VERSION ""

NS_ :

BS_:

BU_: UW_HS2_Bus HSC

BO_ 1972 SigAttack_10ms_10mics: 1 HSC
 SG_ SigAtk_10ms10mics : 0|8@1+ (1,0) [0|255] ""  UW_HS2_Bus

BO_ 1971 SigAttack_10ms_5mics: 1 HSC
 SG_ SigAtk_10ms5mics : 0|8@1+ (1,0) [0|255] ""  UW_HS2_Bus

BO_ 1970 SigAttack_10ms_1mics: 1 HSC
 SG_ SigAtk_10ms1mics : 0|8@1+ (1,0) [0|255] ""  UW_HS2_Bus

BO_ 1973 SigAttack_10ms_0mics: 1 HSC
 SG_ SigAtk_10ms0mics : 0|8@1+ (1,0) [0|255] ""  UW_HS2_Bus

BO_ 1967 SteeringWhl_Signals: 4 HSC
 SG_ StrWhlAngGrd : 16|12@1- (1,0) [-2048|2047] "deg/sec"  UW_HS2_Bus
 SG_ StrWhlAng : 0|16@1- (0.0625,0) [-2048|2047.94] "deg"  UW_HS2_Bus

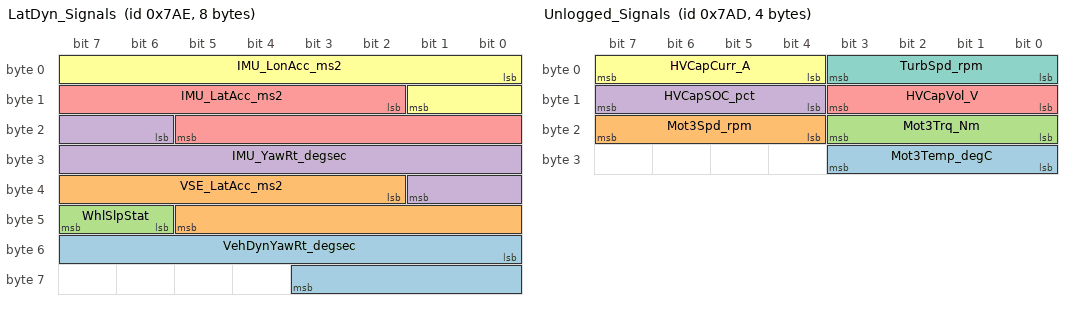
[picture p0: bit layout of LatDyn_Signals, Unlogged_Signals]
BO_ 1966 LatDyn_Signals: 8 HSC
 SG_ VehDynYawRt_degsec : 48|12@1- (0.0625,0) [-128|127.938] "deg/sec"  UW_HS2_Bus
 SG_ VSE_LatAcc_ms2 : 34|12@1- (0.015625,0) [-32|31.9844] "m/s^2"  UW_HS2_Bus
 SG_ WhlSlpStat : 46|2@1+ (1,0) [0|3] ""  UW_HS2_Bus
 SG_ IMU_YawRt_degsec : 22|12@1- (0.0625,0) [-128|127.938] "deg/sec"  UW_HS2_Bus
 SG_ IMU_LatAcc_ms2 : 10|12@1- (0.015625,0) [-32|31.9844] "m/s^2"  UW_HS2_Bus
 SG_ IMU_LonAcc_ms2 : 0|10@1- (0.03,0) [-15.36|15.33] "m/s^2"  UW_HS2_Bus

BO_ 1965 Unlogged_Signals: 4 HSC
 SG_ Mot3Temp_degC : 24|4@1+ (1,0) [0|15] "degC" Vector__XXX
 SG_ Mot3Spd_rpm : 20|4@1+ (1,0) [0|15] "rpm" Vector__XXX
 SG_ Mot3Trq_Nm : 16|4@1+ (1,0) [0|15] "Nm" Vector__XXX
 SG_ HVCapSOC_pct : 12|4@1+ (1,0) [0|15] "%" Vector__XXX
 SG_ HVCapVol_V : 8|4@1+ (1,0) [0|15] "V" Vector__XXX
 SG_ HVCapCurr_A : 4|4@1+ (1,0) [0|15] "A" Vector__XXX
 SG_ TurbSpd_rpm : 0|4@1+ (1,0) [0|15] "rpm" Vector__XXX

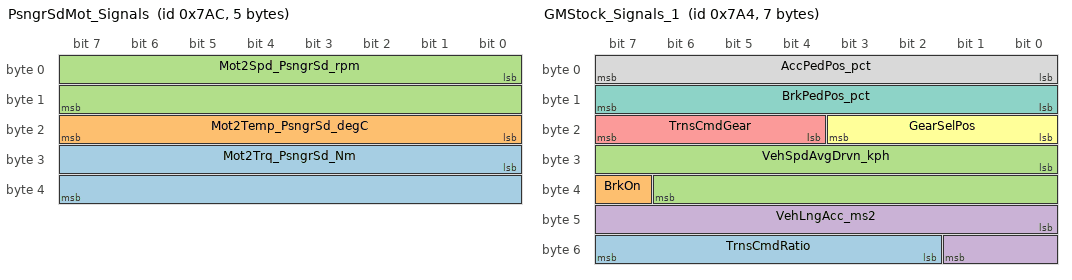
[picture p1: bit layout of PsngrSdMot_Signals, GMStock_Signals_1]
BO_ 1964 PsngrSdMot_Signals: 5 HSC
 SG_ Mot2Trq_PsngrSd_Nm : 24|16@1+ (0.01526,-500) [-500|500.0641] "Nm"  UW_HS2_Bus
 SG_ Mot2Temp_PsngrSd_degC : 16|8@1+ (1,-40) [-40|215] "degC"  UW_HS2_Bus
 SG_ Mot2Spd_PsngrSd_rpm : 0|16@1+ (1,-32767) [-32767|32768] "rpm"  UW_HS2_Bus

BO_ 1956 GMStock_Signals_1: 7 HSC
 SG_ TrnsCmdRatio : 50|6@1+ (0.2,0) [0|12.6] "" Vector__XXX
 SG_ BrkOn : 39|1@1+ (1,0) [0|1] ""  UW_HS2_Bus
 SG_ VehSpdAvgDrvn_kph : 24|15@1+ (0.015625,0) [0|511.984] "km / h"  UW_HS2_Bus
 SG_ VehLngAcc_ms2 : 40|10@1- (0.03,0) [-15.36|15.33] "m/s^2"  UW_HS2_Bus
 SG_ TrnsCmdGear : 20|4@1+ (1,0) [0|15] ""  UW_HS2_Bus
 SG_ GearSelPos : 16|4@1+ (1,0) [0|15] ""  UW_HS2_Bus
 SG_ BrkPedPos_pct : 8|8@1+ (0.392157,0) [0|100] "% full"  UW_HS2_Bus
 SG_ AccPedPos_pct : 0|8@1+ (0.392157,0) [0|100] "%"  UW_HS2_Bus

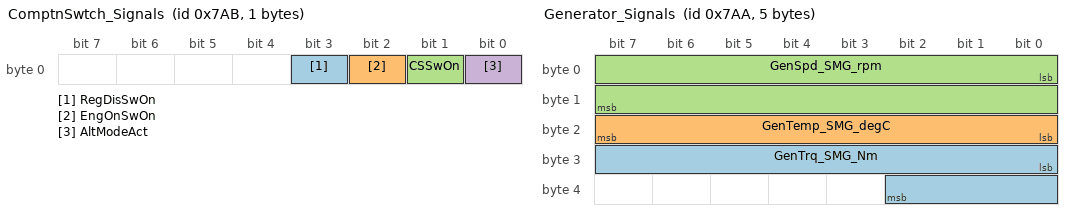
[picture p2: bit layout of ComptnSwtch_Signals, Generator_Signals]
BO_ 1963 ComptnSwtch_Signals: 1 HSC
 SG_ RegDisSwOn : 3|1@1+ (1,0) [0|1] ""  UW_HS2_Bus
 SG_ EngOnSwOn : 2|1@1+ (1,0) [0|1] ""  UW_HS2_Bus
 SG_ CSSwOn : 1|1@1+ (1,0) [0|1] ""  UW_HS2_Bus
 SG_ AltModeAct : 0|1@1+ (1,0) [0|1] ""  UW_HS2_Bus

BO_ 1962 Generator_Signals: 5 HSC
 SG_ GenTrq_SMG_Nm : 24|11@1+ (1,-1023) [-1023|1024] "Nm"  UW_HS2_Bus
 SG_ GenTemp_SMG_degC : 16|8@1+ (1,-40) [-40|215] "degC"  UW_HS2_Bus
 SG_ GenSpd_SMG_rpm : 0|16@1+ (1,-32767) [-32767|32768] "rpm"  UW_HS2_Bus

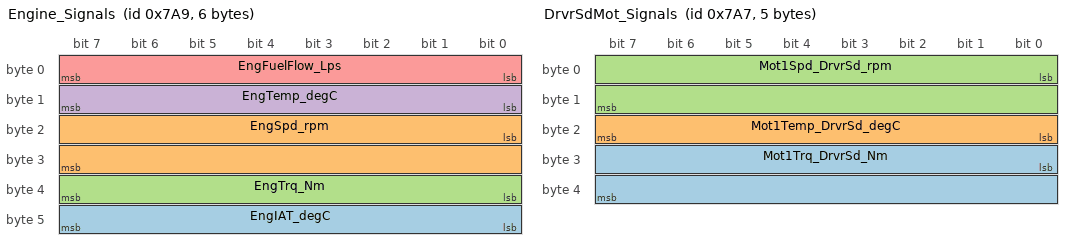
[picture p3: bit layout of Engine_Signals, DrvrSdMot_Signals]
BO_ 1961 Engine_Signals: 6 HSC
 SG_ EngIAT_degC : 40|8@1+ (1,-40) [-40|215] "degC" Vector__XXX
 SG_ EngSpd_rpm : 16|16@1+ (1,-32767) [-32767|32768] "rpm" Vector__XXX
 SG_ EngTrq_Nm : 32|8@1+ (0.3137,0) [0|60] "Nm"  UW_HS2_Bus
 SG_ EngTemp_degC : 8|8@1+ (1,-40) [-40|215] "degC"  UW_HS2_Bus
 SG_ EngFuelFlow_Lps : 0|8@1+ (1,0) [0|0.02] "Litre/s"  UW_HS2_Bus

BO_ 1960 Charger_Signals: 4 HSC
 SG_ ChrgACVolt_V : 16|16@1+ (0.1,0) [0|500] ""  UW_HS2_Bus
 SG_ ChrgACCurr_A : 0|16@1+ (0.01,0) [0|50] ""  UW_HS2_Bus

BO_ 1959 DrvrSdMot_Signals: 5 HSC
 SG_ Mot1Trq_DrvrSd_Nm : 24|16@1+ (0.01526,-500) [-500|500.0641] "Nm"  UW_HS2_Bus
 SG_ Mot1Temp_DrvrSd_degC : 16|8@1+ (1,-40) [-40|215] "degC"  UW_HS2_Bus
 SG_ Mot1Spd_DrvrSd_rpm : 0|16@1+ (1,-32767) [-32767|32768] "rpm"  UW_HS2_Bus

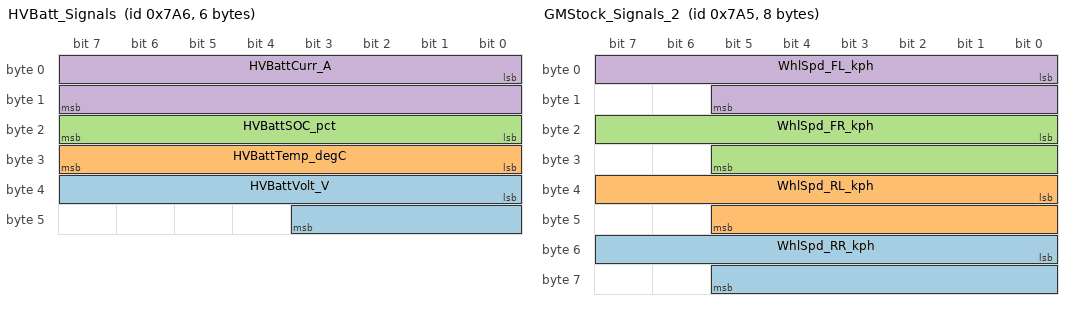
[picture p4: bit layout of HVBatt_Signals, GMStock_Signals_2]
BO_ 1958 HVBatt_Signals: 6 HSC
 SG_ HVBattVolt_V : 32|12@1+ (0.25,0) [0|1000] "Volts"  UW_HS2_Bus
 SG_ HVBattTemp_degC : 24|8@1+ (0.5,-40) [-40|85] "degC"  UW_HS2_Bus
 SG_ HVBattSOC_pct : 16|8@1+ (0.5,0) [0|100] "%"  UW_HS2_Bus
 SG_ HVBattCurr_A : 0|16@1+ (0.025,-1000) [-1000|500] "Amps"  UW_HS2_Bus

BO_ 1957 GMStock_Signals_2: 8 HSC
 SG_ WhlSpd_RR_kph : 48|14@1+ (0.03125,0) [0|511.969] "km / h"  UW_HS2_Bus
 SG_ WhlSpd_RL_kph : 32|14@1+ (0.03125,0) [0|511.969] "km / h"  UW_HS2_Bus
 SG_ WhlSpd_FR_kph : 16|14@1+ (0.03125,0) [0|511.969] "km / h"  UW_HS2_Bus
 SG_ WhlSpd_FL_kph : 0|14@1+ (0.03125,0) [0|511.969] "km / h"  UW_HS2_Bus
